# SWM320 register map
File version: 1.0
SWM320 Microcontroller registers
CPU: CM0 r1p0, little endian, 2 interrupt priority bits
Registers are 32-bit, read-write, no defined reset value unless marked. A register's access mark holds for its fields unless they carry their own. Offsets are from the block's base; lines under a group give offsets from that group; [hi:lo] are bit positions; {n}, {i} and the like mark numbered series; 'fields as' and 'values as' point back to an identical list; <NAME> marks a mode.

## Memory map
0x40000000 SYS size 0x3103C — Registers group
0x40001000 DMA size 0x100 — Registers group
0x40002000 LCD size 0x20 — Registers group
0x40003000 CRC size 0x10 — Registers group
0x40004000 SDIO size 0x40 — Registers group
0x40010000 PORT size 0x664 — Registers group
0x40011000 GPIOA size 0x24 — Registers group
0x40012000 GPIOB size 0x24
0x40013000 GPIOC size 0x24
0x40015000 GPIOM size 0x24
0x40016000 GPION size 0x24
0x40017000 TIMR0 size 0xC — Registers group
0x4001700C TIMR1 size 0xC
0x40017018 TIMR2 size 0xC
0x40017024 TIMR3 size 0xC
0x40017030 TIMR4 size 0xC
0x4001703C TIMR5 size 0xC
0x40017060 TIMRG size 0x1C — Registers group
0x40018000 GPIOP size 0x24
0x40019000 WDT size 0x14 — Registers group
0x4001A000 PWM0 size 0x20 — Registers group
0x4001A020 PWM1 size 0x20
0x4001A040 PWM2 size 0x20
0x4001A060 PWM3 size 0x20
0x4001A080 PWM4 size 0x20
0x4001A0A0 PWM5 size 0x20
0x4001A180 PWMG size 0x58 — Registers group
0x4001B000 RTC size 0x34 — Registers group
0x4001C000 ADC0 size 0xA8 — Registers group
0x4001D000 ADC1 size 0xA8
0x40020000 UART0 size 0x18 — Registers group
0x40021000 UART1 size 0x18
0x40022000 UART2 size 0x18
0x40023000 UART3 size 0x18
0x40028000 I2C0 size 0x20 — Registers group
0x40029000 I2C1 size 0x20
0x4002C000 SPI0 size 0x14 — Registers group
0x4002D000 SPI1 size 0x14
0x40030000 CAN size 0x1B4 — Registers group
0x60000000 NORFLC size 0x18 — Registers group
0x68000000 SRAMC size 0x28 — Registers group
0x78000000 SDRAMC size 0x18 — Registers group

## SYS — Registers group
Base 0x40000000
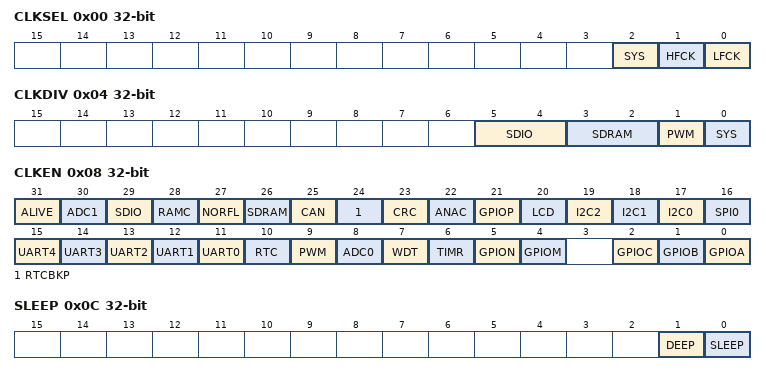
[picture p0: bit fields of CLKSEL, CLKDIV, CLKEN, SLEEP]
0x00 CLKSEL
  [2] SYS, [1] HFCK, [0] LFCK
0x04 CLKDIV
  [5:4] SDIO, [3:2] SDRAM, [1] PWM, [0] SYS
0x08 CLKEN
  [31] ALIVE, [30] ADC1, [29] SDIO, [28] RAMC, [27] NORFL, [26] SDRAM, [25] CAN, [24] RTCBKP, [23] CRC, [22] ANAC, [21] GPIOP, [20] LCD, [19] I2C2, [18] I2C1, [17] I2C0, [16] SPI0, [n+11] UART{n} (n=0..4), [10] RTC, [9] PWM, [8] ADC0, [7] WDT, [6] TIMR, [5] GPION, [4] GPIOM, [2] GPIOC, [1] GPIOB, [0] GPIOA
0x0C SLEEP
  [1] DEEP, [0] SLEEP
0x28 RTCBKP_ISO
0x2C RTCWKEN
0x200 PAWKEN
0x204 PBWKEN
0x208 PCWKEN
0x220 PAWKSR
0x224 PBWKSR
0x228 PCWKSR
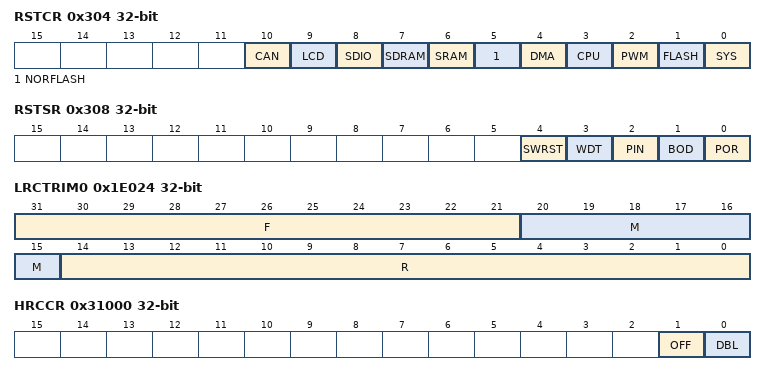
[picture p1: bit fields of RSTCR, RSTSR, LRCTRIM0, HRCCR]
0x304 RSTCR
  [10] CAN, [9] LCD, [8] SDIO, [7] SDRAM, [6] SRAM, [5] NORFLASH, [4] DMA, [3] CPU, [2] PWM, [1] FLASH, [0] SYS
0x308 RSTSR
  [4] SWRST, [3] WDT, [2] PIN, [1] BOD, [0] POR
{0x500+4i} BKP[{i}] (i=0..2)
{0x1E000+4i} RTCBKP[{i}] (i=0..7)
0x1E020 LRCCR
  [0] OFF
0x1E024 LRCTRIM0
  [31:21] F, [20:15] M, [14:0] R
0x1E028 LRCTRIM1
  [14:0] U
0x1E030 RTCLDOTRIM
0x31000 HRCCR
  [1] OFF, [0] DBL
0x31020 XTALCR
  [0] EN
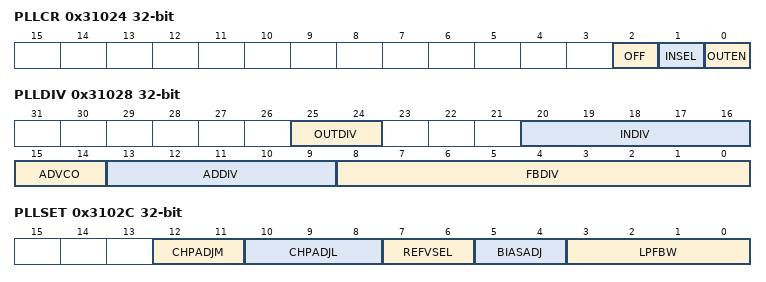
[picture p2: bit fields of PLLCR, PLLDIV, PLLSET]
0x31024 PLLCR
  [2] OFF, [1] INSEL, [0] OUTEN
0x31028 PLLDIV
  [25:24] OUTDIV, [20:16] INDIV, [15:14] ADVCO, [13:9] ADDIV, [8:0] FBDIV
0x3102C PLLSET
  [12:11] CHPADJM, [10:8] CHPADJL, [7:6] REFVSEL, [5:4] BIASADJ, [3:0] LPFBW
0x31030 PLLLOCK
0x31034 BODIE
  [1] _2V2
0x31038 BODIF
  [1] _2V2

## PORT — Registers group
Base 0x40010000
0x00 PORTA_SEL
0x04 PORTB_SEL
0x08 PORTC_SEL
0x20 PORTM_SEL0
0x24 PORTM_SEL1
0x30 PORTN_SEL0
0x34 PORTN_SEL1
0x40 PORTP_SEL0
0x44 PORTP_SEL1
0x100 PORTA_MUX0
0x104 PORTA_MUX1
0x110 PORTB_MUX0
0x114 PORTB_MUX1
0x120 PORTC_MUX0
0x124 PORTC_MUX1
{0x160+4i} PORTM_MUX{i} (i=0..3)
{0x170+4i} PORTN_MUX{i} (i=0..2)
{0x180+4i} PORTP_MUX{i} (i=0..3)
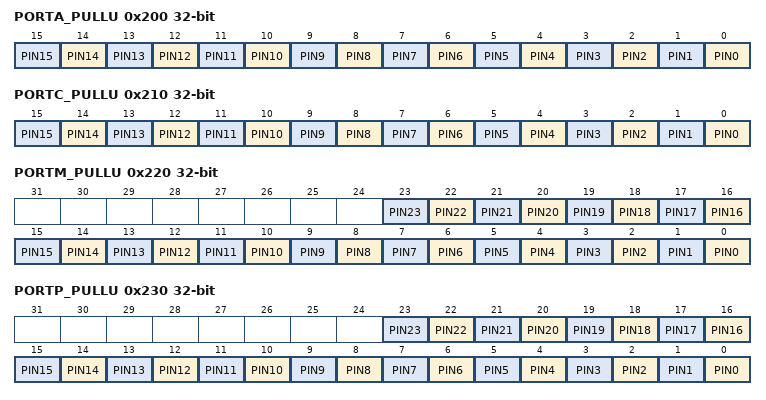
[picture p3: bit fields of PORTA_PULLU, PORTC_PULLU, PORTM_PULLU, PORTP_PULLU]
0x200 PORTA_PULLU
  [n] PIN{n} (n=0..15)
0x210 PORTC_PULLU
  [n] PIN{n} (n=0..15)
0x220 PORTM_PULLU
  [n] PIN{n} (n=0..23)
0x230 PORTP_PULLU
  [n] PIN{n} (n=0..23)
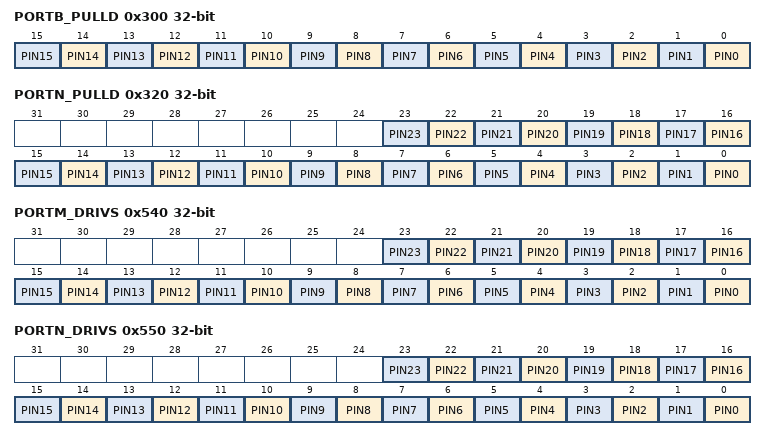
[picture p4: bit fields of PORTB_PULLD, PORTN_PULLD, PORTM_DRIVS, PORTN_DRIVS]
0x300 PORTB_PULLD
  [n] PIN{n} (n=0..15)
0x310 PORTD_PULLD
0x320 PORTN_PULLD
  [n] PIN{n} (n=0..23)
0x540 PORTM_DRIVS
  [n] PIN{n} (n=0..23)
0x550 PORTN_DRIVS
  [n] PIN{n} (n=0..23)
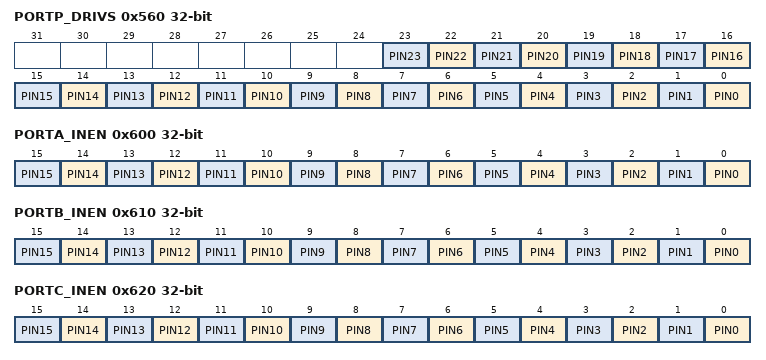
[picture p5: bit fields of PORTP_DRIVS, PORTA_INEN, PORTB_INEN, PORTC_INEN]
0x560 PORTP_DRIVS
  [n] PIN{n} (n=0..23)
0x600 PORTA_INEN
  [n] PIN{n} (n=0..15)
0x610 PORTB_INEN
  [n] PIN{n} (n=0..15)
0x620 PORTC_INEN
  [n] PIN{n} (n=0..15)
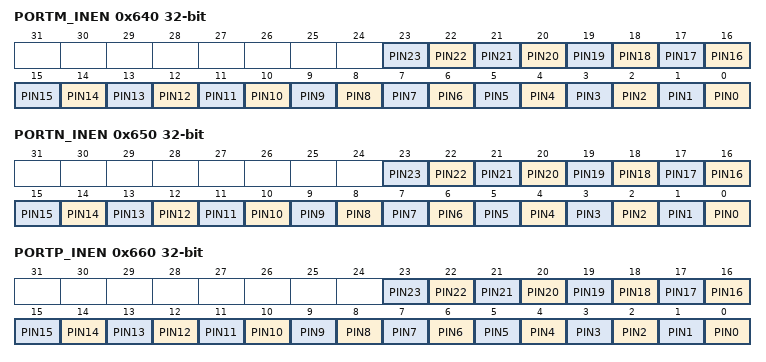
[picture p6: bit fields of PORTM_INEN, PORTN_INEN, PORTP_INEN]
0x640 PORTM_INEN
  [n] PIN{n} (n=0..23)
0x650 PORTN_INEN
  [n] PIN{n} (n=0..23)
0x660 PORTP_INEN
  [n] PIN{n} (n=0..23)
